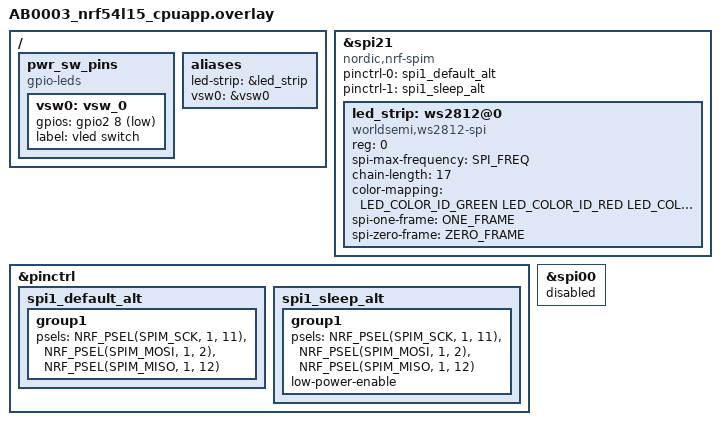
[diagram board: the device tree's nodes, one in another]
/*
 * Copyright (c) 2019, Nordic Semiconductor ASA
 *
 * SPDX-License-Identifier: Apache-2.0
 */

#include <zephyr/dt-bindings/led/led.h>

#include "nrf52-bindings.h"




//&arduino_spi {
&spi21 {
	compatible = "nordic,nrf-spim";compatible = "nordic,nrf-spim";
	pinctrl-0 = <&spi1_default_alt>;
	pinctrl-1 = <&spi1_sleep_alt>;
	pinctrl-names = "default", "sleep";
	
	led_strip: ws2812@0 {
		compatible = "worldsemi,ws2812-spi";

		/* SPI */
		reg = <0>; /* ignored, but necessary for SPI bindings */
		spi-max-frequency = <SPI_FREQ>;

		/* WS2812 */
		chain-length = <17>; /* arbitrary; change at will */
		color-mapping = <LED_COLOR_ID_GREEN
				 LED_COLOR_ID_RED
				 LED_COLOR_ID_BLUE>;
		spi-one-frame = <ONE_FRAME>;
		spi-zero-frame = <ZERO_FRAME>;
	};
};


&pinctrl {
	spi1_default_alt: spi1_default_alt {
		group1 {
			psels = <NRF_PSEL(SPIM_SCK, 1, 11)>,
			        <NRF_PSEL(SPIM_MOSI, 1, 2)>,
			        <NRF_PSEL(SPIM_MISO, 1, 12)>;
		};
	};

	spi1_sleep_alt: spi1_sleep_alt {
		group1 {
			psels = <NRF_PSEL(SPIM_SCK, 1, 11)>,
			        <NRF_PSEL(SPIM_MOSI, 1, 2)>,
			        <NRF_PSEL(SPIM_MISO, 1, 12)>;
			low-power-enable;
		};
	};

};

&spi21 {
	status = "okay";
};

&spi00 {
	status = "disabled";
};

/ {pwr_sw_pins {
		compatible = "gpio-leds";
		vsw0: vsw_0 {
			gpios = <&gpio2 8 GPIO_ACTIVE_LOW>;
			label = "vled switch";
		};
	};
};


/ {
	aliases {
		led-strip = &led_strip;
		vsw0 = &vsw0;
	};
};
